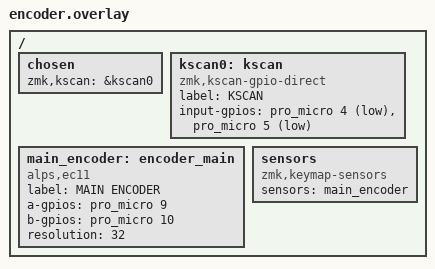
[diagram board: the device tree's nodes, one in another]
/*
 * Copyright (c) 2022 The ZMK Contributors
 *
 * SPDX-License-Identifier: MIT
 */

/ {
	chosen {
		zmk,kscan = &kscan0;
	};

	kscan0: kscan {
		compatible = "zmk,kscan-gpio-direct";

		label = "KSCAN";

		input-gpios
			= <&pro_micro 4 (GPIO_ACTIVE_LOW | GPIO_PULL_UP)>
			, <&pro_micro 5 (GPIO_ACTIVE_LOW | GPIO_PULL_UP)>
			;

	};

    main_encoder: encoder_main {
		compatible = "alps,ec11";
		label = "MAIN ENCODER";
		a-gpios = <&pro_micro 9 (GPIO_ACTIVE_HIGH | GPIO_PULL_UP)>;
		b-gpios = <&pro_micro 10 (GPIO_ACTIVE_HIGH | GPIO_PULL_UP)>;
		resolution = <32>;
	};

	sensors {
		compatible = "zmk,keymap-sensors";
		sensors = <&main_encoder>;
	};

};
